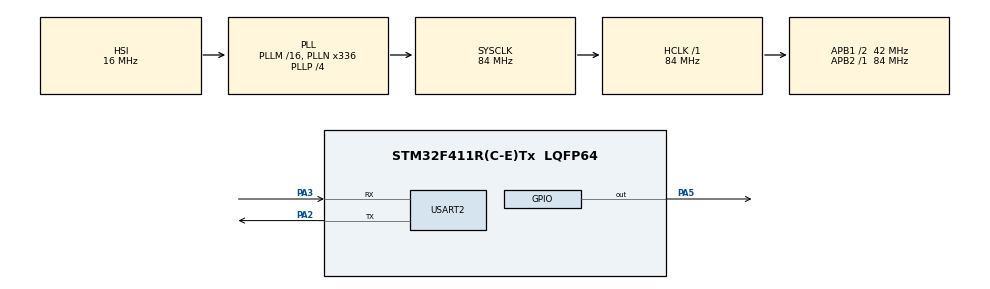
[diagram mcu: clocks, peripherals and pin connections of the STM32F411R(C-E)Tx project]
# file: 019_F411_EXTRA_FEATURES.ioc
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Mcu.Family=STM32F4
Mcu.Name=STM32F411R(C-E)Tx
Mcu.Package=LQFP64
NVIC.PriorityGroup=NVIC_PRIORITYGROUP_0
NVIC.TIM3_IRQn=true\:0\:0\:false\:false\:true\:true\:true\:true
PA13.Mode=Serial_Wire
PA13.Signal=SYS_JTMS-SWDIO
PA14.Mode=Serial_Wire
PA14.Signal=SYS_JTCK-SWCLK
PA2.Mode=Asynchronous
PA2.Signal=USART2_TX
PA3.Mode=Asynchronous
PA3.Signal=USART2_RX
PA5.Signal=GPIO_Output
PC14-OSC32_IN.Mode=LSE-External-Oscillator
PC14-OSC32_IN.Signal=RCC_OSC32_IN
PC15-OSC32_OUT.Mode=LSE-External-Oscillator
PC15-OSC32_OUT.Signal=RCC_OSC32_OUT
PH0\ -\ OSC_IN.Mode=HSE-External-Oscillator
PH0\ -\ OSC_IN.Signal=RCC_OSC_IN
PH1\ -\ OSC_OUT.Mode=HSE-External-Oscillator
PH1\ -\ OSC_OUT.Signal=RCC_OSC_OUT
ProjectManager.HeapSize=0x200
ProjectManager.StackSize=0x400
ProjectManager.TargetToolchain=STM32CubeIDE
RCC.48MHZClocksFreq_Value=84000000
RCC.AHBFreq_Value=84000000
RCC.APB1CLKDivider=RCC_HCLK_DIV2
RCC.APB1Freq_Value=42000000
RCC.APB1TimFreq_Value=84000000
RCC.APB2Freq_Value=84000000
RCC.APB2TimFreq_Value=84000000
RCC.CortexFreq_Value=84000000
RCC.FLatency-AdvancedSettings=FLASH_LATENCY_2
RCC.HCLKFreq_Value=84000000
RCC.HSE_VALUE=8000000
RCC.HSI_VALUE=16000000
RCC.PLLN=336
RCC.PLLP=RCC_PLLP_DIV4
RCC.SYSCLKFreq_VALUE=84000000
RCC.SYSCLKSource=RCC_SYSCLKSOURCE_PLLCLK
RCC.VCOOutputFreq_Value=336000000
TIM3.Period=10000
TIM3.Prescaler=8400
USART2.VirtualMode=VM_ASYNC
VP_TIM3_VS_ClockSourceINT.Mode=Internal
board=NUCLEO-F411RE

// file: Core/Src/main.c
/* USER CODE BEGIN Header */
/**
  ******************************************************************************
  * @file           : main.c
  * @brief          : Main program body
  ******************************************************************************
  * @attention
  *
  * Copyright (c) 2024 STMicroelectronics.
  * All rights reserved.
  *
  * This software is licensed under terms that can be found in the LICENSE file
  * in the root directory of this software component.
  * If no LICENSE file comes with this software, it is provided AS-IS.
  *
  ******************************************************************************
  */
/* USER CODE END Header */
#include "main.h"

/* USER CODE BEGIN PD */

#define SLAVEID 1

/* USER CODE END PD */

TIM_HandleTypeDef htim3;

UART_HandleTypeDef huart2;

uint8_t rxbuffer[100];
uint8_t txbuffer[100];

uint16_t registers[10]={1,255,0,4,3,0,5,2500,3524,55};

uint16_t Modbus_CRC16(uint8_t *data, uint16_t length)
{
    uint16_t crc = 0xFFFF;
    for (int pos = 0; pos < length; pos++)
    {
        crc ^= (uint16_t)data[pos];
        for (int i = 8; i != 0; i--)
        {
            if ((crc & 0x0001) != 0)
            {
                crc >>= 1;
                crc ^= 0xA001;
            }
            else
                crc >>= 1;
        }
    }
    return crc;
}

void SystemClock_Config(void);
static void MX_GPIO_Init(void);
static void MX_USART2_UART_Init(void);
static void MX_TIM3_Init(void);

int main(void)
{

  /* MCU Configuration--------------------------------------------------------*/

  /* Reset of all peripherals, Initializes the Flash interface and the Systick. */
  HAL_Init();

  /* Configure the system clock */
  SystemClock_Config();

  /* Initialize all configured peripherals */
  MX_GPIO_Init();
  MX_USART2_UART_Init();
  MX_TIM3_Init();

  /* Infinite loop */
  while (1)
  {

    /* USER CODE BEGIN 3 */
	 HAL_UART_Receive(&huart2, rxbuffer, sizeof(rxbuffer), 100);
	 if(rxbuffer[0]==1 && rxbuffer[1]== 0x03){
		 uint16_t start_Reg = rxbuffer[2]<<8 | rxbuffer[3];
		 uint16_t num_Reg = rxbuffer[4]<<8 | rxbuffer[5];

		 uint8_t response [5+2*num_Reg+2];
		 response[0] = SLAVEID;
		 response[1] = 0x03;
		 response[2] = 2*num_Reg;
		 for(int i=0; i<num_Reg;i++){
			 response[3+i*2] = (registers[start_Reg+i]>>8) & 0xFF ;
			 response[4+i*2] =	registers[start_Reg+i] & 0xFF ;
		 }

		 uint16_t CRC2 = Modbus_CRC16(response, 3+2*num_Reg);
		 response[3 + 2*num_Reg] = CRC2 & 0xFF;
		 response[4 + 2*num_Reg] = (CRC2>>8) & 0xFF;

		 int response_size = (3+2*num_Reg+2);
		 HAL_UART_Transmit(&huart2, response, response_size, 100);

	 }
	 else if(rxbuffer[0]==1 && rxbuffer[1]==0x10){
		 uint16_t start_Reg =(rxbuffer[2]<<8) | rxbuffer[3];
		 uint16_t num_Reg = (rxbuffer[4]<<8) | rxbuffer[5];
		 uint8_t num_of_databytes = rxbuffer[6];

		 for(int i=0;i<num_Reg;i++){
			 registers[start_Reg+i] = (rxbuffer[7+2*i])<<8 | rxbuffer[8+2*i];
		 }

		 //Preapering response
		 txbuffer[0]=SLAVEID;
		 txbuffer[1]=0x10;
		 txbuffer[2]=rxbuffer[2];
		 txbuffer[3]=rxbuffer[3];
		 txbuffer[4]=rxbuffer[4];
		 txbuffer[5]=rxbuffer[5];

		 uint16_t CRC2 = Modbus_CRC16(txbuffer, 6);
		 txbuffer[6] = CRC2 & 0xFF;
		 txbuffer[7] = (CRC2>>8) & 0xFF;

		 HAL_UART_Transmit(&huart2, txbuffer, 8, 100);
	 }
	  else if ((rxbuffer[0]==SLAVEID) && (rxbuffer[1]==0x06)){  	// EĞER SLAVE ADRESİ VE FONKSİYON 0x06 İSE
	 	  	  		{

	 	  	  		uint16_t address = (rxbuffer[2]<<8) | rxbuffer[3];
	 	  	  		uint16_t value = ((rxbuffer[4]<<8) | rxbuffer[5]);

	 	  	  		registers[address] = value;										// Register'a yazma

	 	  	  		 uint8_t response[8];
	 	  	  		for (int i = 0; i < 6; i++) {								// Cevabı hazırlama
	 	  	  		response[i] = rxbuffer[i];
	 	  	  		}

	 	  	  		uint16_t crc = Modbus_CRC16(response, 6);					// CRC hesaplama
	 	  	  		response[6] = crc & 0xFF;
	 	  	  		response[7] = (crc >> 8) & 0xFF;

	 	  	  		 // Cevabı gönder
	 	  	  		HAL_UART_Transmit(&huart2, response, 8, 1000);
	 	  	  			  }

	 	  	  	  }
	  else if (rxbuffer[0] == SLAVEID && rxbuffer[1] == 0x04) { // Slave ID ve Fonksiyon kodu kontrolü
	         uint16_t startAddress = (rxbuffer[2] << 8) | rxbuffer[3]; // Başlangıç adresi
	         uint16_t numRegisters = (rxbuffer[4] << 8) | rxbuffer[5]; // Okunacak register sayısı

	         uint8_t response[5 + 2 * numRegisters + 2]; // Cevap mesajı için buffer

	         // Cevap mesajının başlık kısmı
	         response[0] = SLAVEID;
	         response[1] = 0x04; // Function code (Read Input Registers)
	         response[2] = 2 * numRegisters; // Byte sayısı (her register 2 byte)

	         // Register verilerini ekle
	         for (int i = 0; i < numRegisters; i++) {
	             uint16_t value = registers[startAddress + i]; // Register değerini al
	             response[3 + i * 2] = (value >> 8) & 0xFF; // Üst byte
	             response[4 + i * 2] = value & 0xFF; // Alt byte
	         }

	         // CRC hesapla ve ekle
	         uint16_t crc = Modbus_CRC16(response, 3 + 2 * numRegisters);
	         response[3 + 2 * numRegisters] = crc & 0xFF; // CRC düşük byte
	         response[4 + 2 * numRegisters] = (crc >> 8) & 0xFF; // CRC yüksek byte

	         // Cevabı gönder
	         HAL_UART_Transmit(&huart2, response, 5 + 2 * numRegisters + 2, 1000);

  }
  /* USER CODE END 3 */
}

void SystemClock_Config(void)
{
  RCC_OscInitTypeDef RCC_OscInitStruct = {0};
  RCC_ClkInitTypeDef RCC_ClkInitStruct = {0};

  /** Configure the main internal regulator output voltage
  */
  __HAL_RCC_PWR_CLK_ENABLE();
  __HAL_PWR_VOLTAGESCALING_CONFIG(PWR_REGULATOR_VOLTAGE_SCALE1);

  /** Initializes the RCC Oscillators according to the specified parameters
  * in the RCC_OscInitTypeDef structure.
  */
  RCC_OscInitStruct.OscillatorType = RCC_OSCILLATORTYPE_HSI;
  RCC_OscInitStruct.HSIState = RCC_HSI_ON;
  RCC_OscInitStruct.HSICalibrationValue = RCC_HSICALIBRATION_DEFAULT;
  RCC_OscInitStruct.PLL.PLLState = RCC_PLL_ON;
  RCC_OscInitStruct.PLL.PLLSource = RCC_PLLSOURCE_HSI;
  RCC_OscInitStruct.PLL.PLLM = 16;
  RCC_OscInitStruct.PLL.PLLN = 336;
  RCC_OscInitStruct.PLL.PLLP = RCC_PLLP_DIV4;
  RCC_OscInitStruct.PLL.PLLQ = 4;
  if (HAL_RCC_OscConfig(&RCC_OscInitStruct) != HAL_OK)
  {
    Error_Handler();
  }

  /** Initializes the CPU, AHB and APB buses clocks
  */
  RCC_ClkInitStruct.ClockType = RCC_CLOCKTYPE_HCLK|RCC_CLOCKTYPE_SYSCLK
                              |RCC_CLOCKTYPE_PCLK1|RCC_CLOCKTYPE_PCLK2;
  RCC_ClkInitStruct.SYSCLKSource = RCC_SYSCLKSOURCE_PLLCLK;
  RCC_ClkInitStruct.AHBCLKDivider = RCC_SYSCLK_DIV1;
  RCC_ClkInitStruct.APB1CLKDivider = RCC_HCLK_DIV2;
  RCC_ClkInitStruct.APB2CLKDivider = RCC_HCLK_DIV1;

  if (HAL_RCC_ClockConfig(&RCC_ClkInitStruct, FLASH_LATENCY_2) != HAL_OK)
  {
    Error_Handler();
  }
}

static void MX_TIM3_Init(void)
{

  TIM_ClockConfigTypeDef sClockSourceConfig = {0};
  TIM_MasterConfigTypeDef sMasterConfig = {0};

  htim3.Instance = TIM3;
  htim3.Init.Prescaler = 8400;
  htim3.Init.CounterMode = TIM_COUNTERMODE_UP;
  htim3.Init.Period = 10000;
  htim3.Init.ClockDivision = TIM_CLOCKDIVISION_DIV1;
  htim3.Init.AutoReloadPreload = TIM_AUTORELOAD_PRELOAD_DISABLE;
  if (HAL_TIM_Base_Init(&htim3) != HAL_OK)
  {
    Error_Handler();
  }
  sClockSourceConfig.ClockSource = TIM_CLOCKSOURCE_INTERNAL;
  if (HAL_TIM_ConfigClockSource(&htim3, &sClockSourceConfig) != HAL_OK)
  {
    Error_Handler();
  }
  sMasterConfig.MasterOutputTrigger = TIM_TRGO_RESET;
  sMasterConfig.MasterSlaveMode = TIM_MASTERSLAVEMODE_DISABLE;
  if (HAL_TIMEx_MasterConfigSynchronization(&htim3, &sMasterConfig) != HAL_OK)
  {
    Error_Handler();
  }

}

static void MX_USART2_UART_Init(void)
{

  huart2.Instance = USART2;
  huart2.Init.BaudRate = 115200;
  huart2.Init.WordLength = UART_WORDLENGTH_8B;
  huart2.Init.StopBits = UART_STOPBITS_1;
  huart2.Init.Parity = UART_PARITY_NONE;
  huart2.Init.Mode = UART_MODE_TX_RX;
  huart2.Init.HwFlowCtl = UART_HWCONTROL_NONE;
  huart2.Init.OverSampling = UART_OVERSAMPLING_16;
  if (HAL_UART_Init(&huart2) != HAL_OK)
  {
    Error_Handler();
  }

}

static void MX_GPIO_Init(void)
{
  GPIO_InitTypeDef GPIO_InitStruct = {0};

  /* GPIO Ports Clock Enable */
  __HAL_RCC_GPIOC_CLK_ENABLE();
  __HAL_RCC_GPIOH_CLK_ENABLE();
  __HAL_RCC_GPIOA_CLK_ENABLE();

  /*Configure GPIO pin Output Level */
  HAL_GPIO_WritePin(GPIOA, GPIO_PIN_5, GPIO_PIN_RESET);

  /*Configure GPIO pin : PA5 */
  GPIO_InitStruct.Pin = GPIO_PIN_5;
  GPIO_InitStruct.Mode = GPIO_MODE_OUTPUT_PP;
  GPIO_InitStruct.Pull = GPIO_NOPULL;
  GPIO_InitStruct.Speed = GPIO_SPEED_FREQ_LOW;
  HAL_GPIO_Init(GPIOA, &GPIO_InitStruct);

}

void Error_Handler(void)
{
  __disable_irq();
  while (1)
  {
  }
}
